# pmac_tx_secure register map
Vendor: Texas Instruments
Registers are 32-bit, access per field, reset 0x0 unless marked. A register's access mark holds for its fields unless they carry their own. Offsets are as the file gives them; [hi:lo] are bit positions; {n}, {i} and the like mark numbered series; <NAME> marks a mode.

## pmac_tx_secure (part 3 of 3)
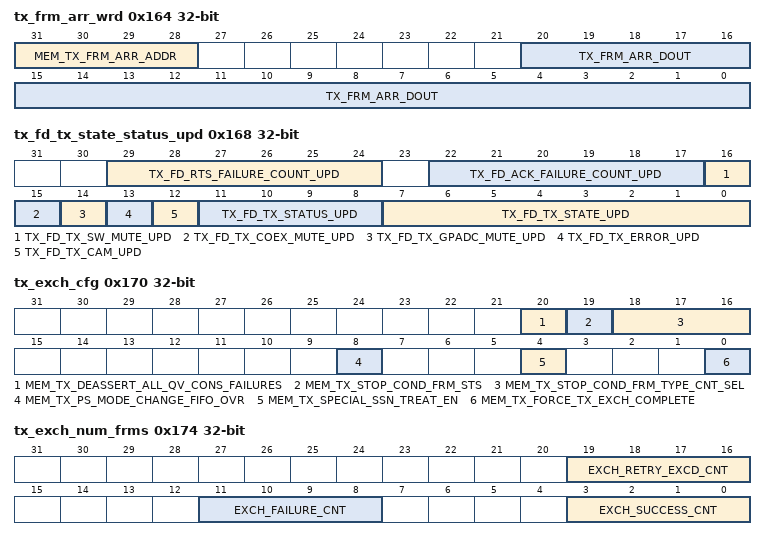
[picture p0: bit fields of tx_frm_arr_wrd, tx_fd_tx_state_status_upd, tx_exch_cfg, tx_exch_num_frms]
0x164 tx_frm_arr_wrd
  [31:28] MEM_TX_FRM_ARR_ADDR rw
  [20:0] TX_FRM_ARR_DOUT ro — read an entry from the trigger/exchange tx_frm_fifo. this is for debug only and can be used only when exchange is idle. the address is taken from the TX_FRM_ARR_ADDR when the array is not accessed by exchange.
0x168 tx_fd_tx_state_status_upd ro — an updated version of the TX_FD_STATE_STATUS. after loading the TX_FD_STATE_STATUS register, this register contains the incremented/cleared coutner values.
  [29:24] TX_FD_RTS_FAILURE_COUNT_UPD — updated failure count to be written to memory/descriptor,
  [22:17] TX_FD_ACK_FAILURE_COUNT_UPD — updated failure count to be written to memory/descriptor,
  [16] TX_FD_TX_SW_MUTE_UPD
  [15] TX_FD_TX_COEX_MUTE_UPD
  [14] TX_FD_TX_GPADC_MUTE_UPD
  [13] TX_FD_TX_ERROR_UPD
  [12] TX_FD_TX_CAM_UPD
  [11:8] TX_FD_TX_STATUS_UPD — updated State to be written to memory/descriptor,
  [7:0] TX_FD_TX_STATE_UPD — updated State to be written to memory/descriptor,
0x16C tx_dummy_reg — auxiliary scripter status. serves just as a read/write address for scripter usages.
  [0] MEM_DUMMY rw — regular read/write register. note that tx scripters write and read from this address.
0x170 tx_exch_cfg reset not defined
  [20] MEM_TX_DEASSERT_ALL_QV_CONS_FAILURES rw — when set, check and deassert all QVs if link's consecutive failure threshold was crossed. if cleared, ignore this event.
  [19] MEM_TX_STOP_COND_FRM_STS rw — 1 : all frames are counted (success, fail etc) 0:successful frame sonly are counted - - PPDU: BA received for aggregation is success - MSDU: for aggregation ,bitmap should be considered - MPDU: for aggregation ,bitmap should be considered
  [18:16] MEM_TX_STOP_COND_FRM_TYPE_CNT_SEL rw — select which kind of transmission will be counted for frame numbe rstop condition: 000: PPDU 001: MSDU (each non-fragmented MPDU + last MPDU fragment) 010 and up: MPDU (incl each fragment)
  [8] MEM_TX_PS_MODE_CHANGE_FIFO_OVR rw — when set, tx frames which cause PS mode change will be pushed to tx_exchange fifo.
  [4] MEM_TX_SPECIAL_SSN_TREAT_EN rw — when set, in case a BA arrives with its SSN field > transmitted frame's sequence number, it is parsed as if it will never be acked. in this case, frame will be marked as if retry limit was exeeded when cleared, frame will be marked as failed and may require a retry.
  [0] MEM_TX_FORCE_TX_EXCH_COMPLETE rw — force select the tx exchange complete FIFO as the destination for all non-retry frames.
0x174 tx_exch_num_frms ro
  [19:16] EXCH_RETRY_EXCD_CNT — number of frames in aggregation which are below SSN and enabled to be clasified as retry exceeded for that reason
  [11:8] EXCH_FAILURE_CNT — number of frames in aggregation which were not AKCed or otherwise decided as failed
  [3:0] EXCH_SUCCESS_CNT — number of frames in aggregation which were AKCed as part of an aggregation
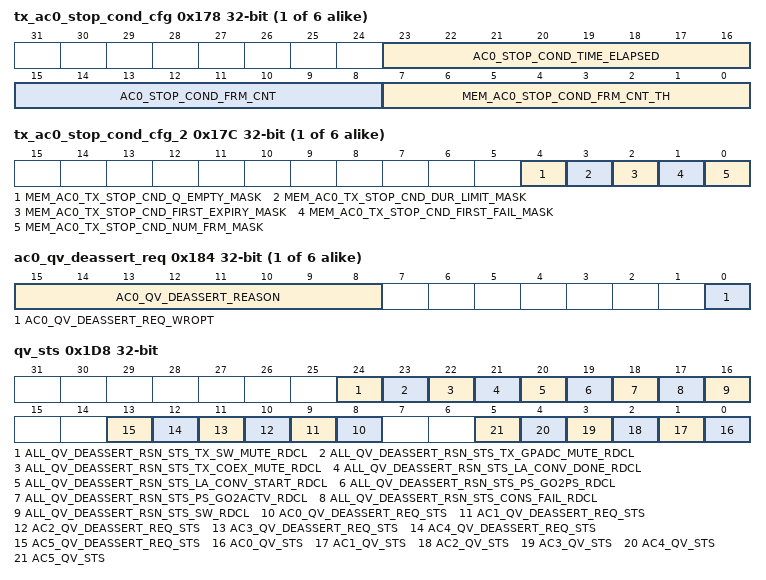
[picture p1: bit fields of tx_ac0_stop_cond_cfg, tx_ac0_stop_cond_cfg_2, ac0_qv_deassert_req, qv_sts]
{0x178+0x10*i} tx_ac{i}_stop_cond_cfg (i=0..5)
  [23:16] AC{i}_STOP_COND_TIME_ELAPSED ro — time from QV assertion.
  [15:8] AC{i}_STOP_COND_FRM_CNT ro — number of frames until stop condition may be applied. frame type is determined by TX_EXCH_CFG register.
  [7:0] MEM_AC{i}_STOP_COND_FRM_CNT_TH rw — number of frames until stop condition may be applied. frame type is determined by TX_EXCH_CFG register.
{0x17C+0x10*i} tx_ac{i}_stop_cond_cfg_2 (i=0..5)
  [4] MEM_AC{i}_TX_STOP_CND_Q_EMPTY_MASK rw, [3] MEM_AC{i}_TX_STOP_CND_DUR_LIMIT_MASK rw, [2] MEM_AC{i}_TX_STOP_CND_FIRST_EXPIRY_MASK rw, [1] MEM_AC{i}_TX_STOP_CND_FIRST_FAIL_MASK rw, [0] MEM_AC{i}_TX_STOP_CND_NUM_FRM_MASK rw
{0x180+0x10*i} ac{i}_qv (i=0..5)
  [0] AC{i}_QV_WROPT rw — queue valid bit. set by FW and cleared by HW. SW may pend a deassertion request via the deassert regs. writing 0 to this address will be ignored.
{0x184+0x10*i} ac{i}_qv_deassert_req (i=0..5)
  [15:8] AC{i}_QV_DEASSERT_REASON ro — bit 0: SW request. bit 1: Candidate Failure. bit 2: TSF Limit Excceded bit 3: Quit when Queue Empty bit 4: Frame Count bit 5: First Fail bit 6: First Expiry bit 7: Duration Limit Excced.
  [0] AC{i}_QV_DEASSERT_REQ_WROPT rw
0x1D8 qv_sts ro — read only status of the Queues condition - QV, QV_DEASSERT etc.
  [24] ALL_QV_DEASSERT_RSN_STS_TX_SW_MUTE_RDCL — ALL qv deasserted due to link adaptation operation mode change (convergence done).
  [23] ALL_QV_DEASSERT_RSN_STS_TX_GPADC_MUTE_RDCL — ALL qv deasserted due to link adaptation operation mode change (convergence done).
  [22] ALL_QV_DEASSERT_RSN_STS_TX_COEX_MUTE_RDCL — ALL qv deasserted due to link adaptation operation mode change (convergence done).
  [21] ALL_QV_DEASSERT_RSN_STS_LA_CONV_DONE_RDCL — ALL qv deasserted due to link adaptation operation mode change (convergence done).
  [20] ALL_QV_DEASSERT_RSN_STS_LA_CONV_START_RDCL — ALL qv deasserted due to link adaptation operation mode change (convergence start).
  [19] ALL_QV_DEASSERT_RSN_STS_PS_GO2PS_RDCL — ALL qv deasserted due to power save mode change
  [18] ALL_QV_DEASSERT_RSN_STS_PS_GO2ACTV_RDCL — ALL qv deasserted due to power save mode change
  [17] ALL_QV_DEASSERT_RSN_STS_CONS_FAIL_RDCL — ALL qv deasserted due to consequtive failure threshold crossing
  [16] ALL_QV_DEASSERT_RSN_STS_SW_RDCL — ALL qv deasserted due to SW request
  [n+8] AC{n}_QV_DEASSERT_REQ_STS (n=0..5) — status of qc deassert request (pending/clear). include this AC's deassert request ORed with the deassert all request.
  [n] AC{n}_QV_STS (n=0..5) — RO of AC{n}_QV bit
0x1DC qv_bitmap
  [5:0] QV_BITMAP_WROPT rw — qv set bitmap - setting a bit will set the relevant AC's QV bit. reading this register will return all ACs QV bit status. reading this address will return the qv status of the 6 ACs. writing 0 to this address will be ignored.
0x1E0 qv_deassert_bitmap
  [5:0] QV_DEASSERT_BITMAP_WROPT rw — setting each bit will create a deassert request to the relevant AC. writing 0 to this address will be ignore. reading this address will return the status of this request: 1 - deassertion pending 0 - idle/done
0x1E4 qv_deassert_all
  [0] QV_DEASSERT_ALL_WRCL wo — setting this bit will create a deassertion request on all ACs. when all ACs are cleared, and interrupt will be asserted. writing 0 to this address will be ignored.
0x1E8 qv_deassert_reason_all ro
  [8:0] ALL_QV_DEASSERT_REASON_RDCL — status of the 'de-assert all' sources, write 0 to clear. sources bitmap: [8] TX mute due to Coex de-grant. [7] TX mute due to GPADC (Thermal). [6] TX mute due to SW request. [5] a link moved to LA functional mode [4] a link moved to LA convergence mode [3] a link moved to PS mode [2] a link moved to active mode [1] a link crossed the consecutive failure threshold [0] SW request for all qv deassertion
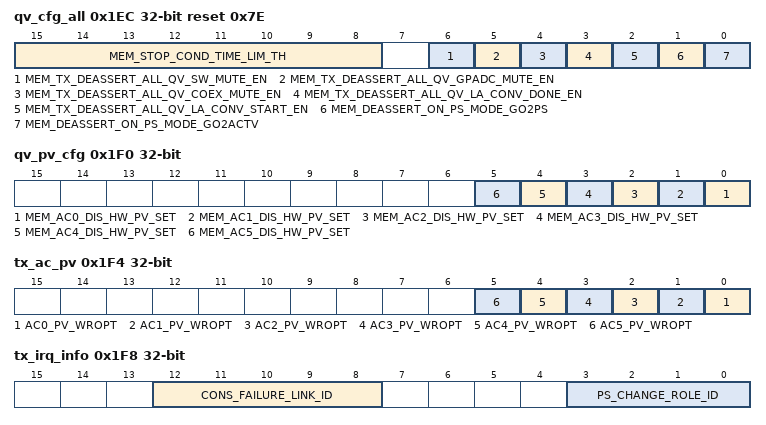
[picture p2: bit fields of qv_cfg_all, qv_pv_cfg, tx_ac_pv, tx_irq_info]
0x1EC qv_cfg_all reset 0x7E
  [15:8] MEM_STOP_COND_TIME_LIM_TH rw — time to be used as a stop condition starting at QV assertion. 9 lsb of the TSF are ignored giving 512usec resolutions. apply to all ACs
  [6] MEM_TX_DEASSERT_ALL_QV_SW_MUTE_EN rw
  [5] MEM_TX_DEASSERT_ALL_QV_GPADC_MUTE_EN rw
  [4] MEM_TX_DEASSERT_ALL_QV_COEX_MUTE_EN rw
  [3] MEM_TX_DEASSERT_ALL_QV_LA_CONV_DONE_EN rw
  [2] MEM_TX_DEASSERT_ALL_QV_LA_CONV_START_EN rw
  [1] MEM_DEASSERT_ON_PS_MODE_GO2PS rw — when set, any link which changes state from active to power save will create a QV de-assert request to all ACs. power save mode change is detected by rx.
  [0] MEM_DEASSERT_ON_PS_MODE_GO2ACTV rw — when set, any link which changes state to from power save to active will create a QV de-assert request to all ACs. power save mode change is detected by rx.
0x1F0 qv_pv_cfg
  [n] MEM_AC{n}_DIS_HW_PV_SET rw (n=0..5) — when set, candidate done will not set the pv. upon candidate completion, an interrupt to SW will be triggered and SW may assert pv.
0x1F4 tx_ac_pv — packet valid indication - if enabled, tx_candidate will assert this bit. if disabled (register QV_PV_CFG) - candidate will not set pv after completion and SW should set the PV bit/s
  [n] AC{n}_PV_WROPT rw (n=0..5)
0x1F8 tx_irq_info ro
  [12:8] CONS_FAILURE_LINK_ID — active link id on last consecutive failure threshold crossing. latched on every thresh cross event.
  [3:0] PS_CHANGE_ROLE_ID — active role id on last ps mode change. latched on every ps mode change event.
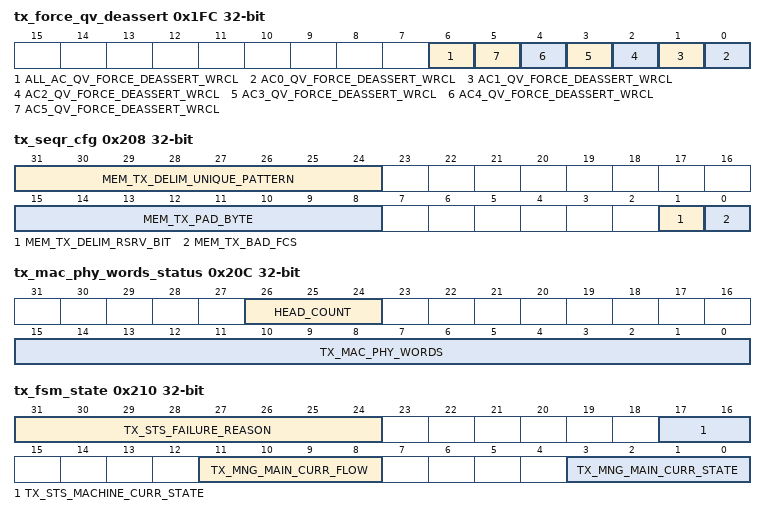
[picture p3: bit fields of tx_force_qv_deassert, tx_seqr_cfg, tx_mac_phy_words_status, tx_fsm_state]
0x1FC tx_force_qv_deassert
  [6] ALL_AC_QV_FORCE_DEASSERT_WRCL wo — writing 1 to this bit will clear all qv and qv deassert request. this applies to single qv and for common qv deassert requests.
  [n] AC{n}_QV_FORCE_DEASSERT_WRCL wo (n=0..5) — writing 1 to this bit will clear both qv and qv deassert request.
0x200 tx_spare_0
  [15:0] TX_SPARE_0_WROPT rw
0x204 tx_spare_1 rw
  [31:0] TX_SPARE_1_WROPT
0x208 tx_seqr_cfg reset not defined
  [31:24] MEM_TX_DELIM_UNIQUE_PATTERN rw — value to be used on head delimiter N pattern
  [15:8] MEM_TX_PAD_BYTE rw — used for padding between mpdus.
  [1] MEM_TX_DELIM_RSRV_BIT rw
  [0] MEM_TX_BAD_FCS rw — when set, flip a bit in the 32bit FCS (corrupt the tx fcs)
0x20C tx_mac_phy_words_status ro — This register holds the MAC-PHY words.
  [26:24] HEAD_COUNT — number of TX_VECTORS words transfered from MAC to PHY. Should be 4.
  [15:0] TX_MAC_PHY_WORDS — number of words transfered from MAC to PHY. this counts is clear on tx_frm_stb (end of frame) and countes on read from PHY. Note, count only data (not header words).
0x210 tx_fsm_state ro — TX FSM State (TX_FSM_STATE)
  [31:24] TX_STS_FAILURE_REASON — bit 0: FCS failure bit 1: Block ACK with Broadcast Address but not Multi-STA Block ACK. bit 2: Multi-STA Block ACK without AID match. bit 3: un-expected RX received (may be the result of FCS) bit 4: RX ended before other indications arrived (e.g AMPDU where no head delimiter was detected) bit 5: Frame aborted before it was over (PHY abort, reject, memory issue etc) bit 6: PLCP header did not arrive
  [17:16] TX_STS_MACHINE_CURR_STATE — tx manager status machine - 0 - idle (true for cases where no response is required as well) 1 - wait for rx status
  [11:8] TX_MNG_MAIN_CURR_FLOW — 0: TX_MAIN_FLOW_IDLE 1: TX_MAIN_FLOW_PROT 2: TX_MAIN_FLOW_DATA 3: TX_MAIN_FLOW_TB_DATA 4: TX_MAIN_FLOW_CF_END 5: TX_MAIN_FLOW_RESP
  [3:0] TX_MNG_MAIN_CURR_STATE — 0: TX_MAIN_IDLE 1: TX_MAIN_WAIT_TRIG_DN 2: TX_MAIN_AGGR_WAIT_NXT 3: TX_MAIN_WAIT_BURST_CAND 4: TX_MAIN_WAIT_STS 5: TX_MAIN_WAIT_EXCH
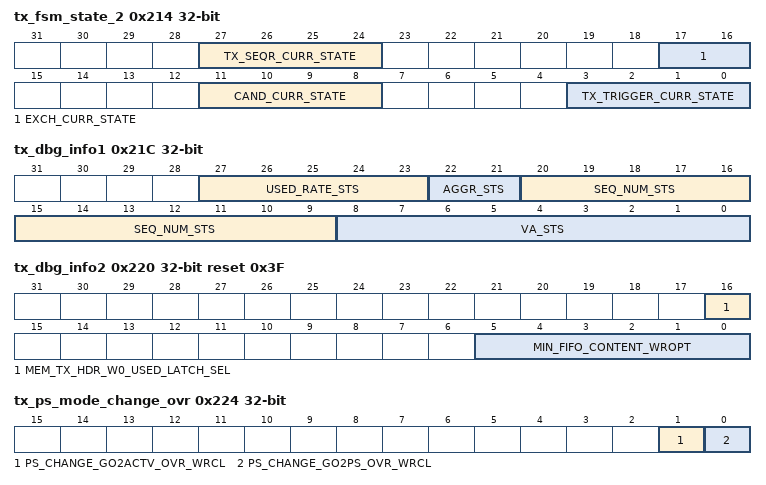
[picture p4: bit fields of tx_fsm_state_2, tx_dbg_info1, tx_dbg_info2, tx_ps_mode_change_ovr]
0x214 tx_fsm_state_2 ro
  [27:24] TX_SEQR_CURR_STATE — 4'd0 : IDLE 4'd1 : WAIT_MPDU_RDY 4'd2 : HEAD_DELIM_WR 4'd3 : FRM_BODY_WR 4'd4 : FCS_WR 4'd5 : PAD_WR 4'd6 : TAIL_DELIM_WR 4'd7 : SYM_PAD_WR 4'd8 : WAIT_FIFO_EMPTY 4'd9 : WAIT_TX_DONE 4'd10 : WAIT_TX_HOLD
  [17:16] EXCH_CURR_STATE — 0: IDLE 1: EXCH_LOAD_REGS 2: EXCH_STORE_REGS 3: EXCH_EVENT_LOG
  [11:8] CAND_CURR_STATE — 4'h0 : IDLE 4'h1 : GATHER_INFO 4'h2 : GET_RATE 4'h3 : CALC_AGGR_DUR 4'h4 : CALC_DATA_DUR 4'h5 : CALC_DATA_IR_DUR 4'h6 : CALC_PROT_DUR 4'h7 : CALC_PROT_IR_DUR 4'h8 : CHK_TXOP_LIMIT 4'h9 : CALC_FRAG_BYTES 4'hA : CALC_FRAG_DUR 4'hB : CHK_FRAG_PROT 4'hC : CANDIDATE_DONE
  [3:0] TX_TRIGGER_CURR_STATE — 4'd0 : TRIG_STATE_IDLE 4'd1 : TRIG_STATE_GATHER_INFO 4'd2 : TRIG_STATE_BUILD_AGGR 4'd3 : TRIG_STATE_CHK_BURST 4'd4 : TRIG_STATE_CALC_IR_DUR 4'd5 : TRIG_STATE_CALC_PARTIAL_DUR 4'd6 : TRIG_STATE_SET_PHY_PARAMS 4'd7 : TRIG_STATE_SET_CMD 4'd8 : TRIG_STATE_UPD_WLAN_HDR 4'd9 : TRIG_STATE_FETCH_WLAN_HDR 4'd10 : TRIG_STATE_PREP_FRM
0x218 tx_winner_tsf_latch_for_exch ro
  [31:0] TX_WINNER_TSF_LATCH_FOR_EXCH — latch the tx winner tsf upon entering the tx trigger. this field can be used by the tx_exchange for writing to the descriptor. for that purpose, if a new tx_winner_stb occured between the tx_trigger and tx_exch, this field will retain its value.
0x21C tx_dbg_info1 ro
  [27:23] USED_RATE_STS
  [22:21] AGGR_STS — 00 - not part of aggr 01 - first in aggr 10 - middle frame 11 - last frame.
  [20:9] SEQ_NUM_STS — sequence number of transmitted frame. in agrregation it will contain the current treated frame (in case this register is read inside the exchange aggr loop)
  [8:0] VA_STS — descriptor ID / Virtual Address of transmitted frame
0x220 tx_dbg_info2 reset 0x3F
  [16] MEM_TX_HDR_W0_USED_LATCH_SEL rw — Select the Header W0 latching trigger: Set 0: trigger by: tx_winner_stb_synched (New for LSB-PG2) Set 1: trigger by: (head_count == 3'h0) & tx_header_rd (legacy)
  [5:0] MIN_FIFO_CONTENT_WROPT rw — holds the minimum number of bytes that the tx fifo reached. its reset value is 0x31. it latches the minimum value under the following conditions: current ppdu length is higher then current min. start latch after at least 5 words were written to the fifo latch as long as tx is writing to the fifo.
0x224 tx_ps_mode_change_ovr — writing '1' to one of the bits will create a pulse in one of the PSD inputs to the tx. this pulse is 'OR'ed with the rx inputs.
  [1] PS_CHANGE_GO2ACTV_OVR_WRCL wo, [0] PS_CHANGE_GO2PS_OVR_WRCL wo
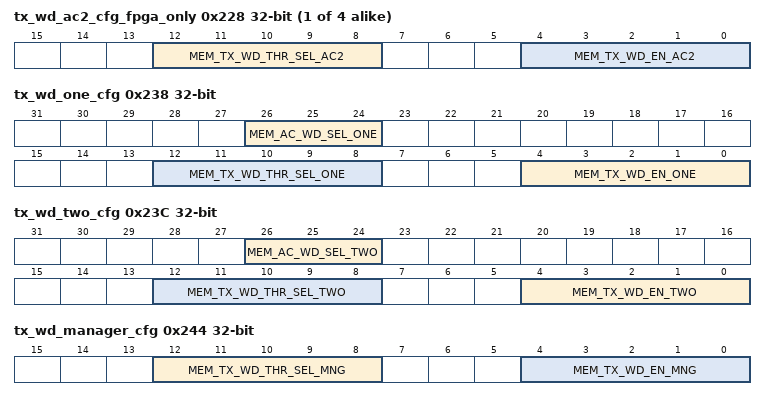
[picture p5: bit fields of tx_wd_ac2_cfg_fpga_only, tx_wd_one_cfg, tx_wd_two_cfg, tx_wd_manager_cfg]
{0x220+4i} tx_wd_ac{i}_cfg_fpga_only reset not defined (i=2..5)
  [12:8] MEM_TX_WD_THR_SEL_AC{i} rw — AC{i} FSM Watchdog threshold select. air dependant states (IDLE, WAIT_TX_START and WAIT_TX_DONE) use msec (low freq) resolution. other use usec (high freq) resolution this bit select which threshold of the corresponding resolution is used.
  [4:0] MEM_TX_WD_EN_AC{i} rw — AC{i} FSM Watchdog en, one bit per FSM state
0x238 tx_wd_one_cfg reset not defined
  [26:24] MEM_AC_WD_SEL_ONE rw — second AC machine Watchdog selected AC
  [12:8] MEM_TX_WD_THR_SEL_ONE rw — second AC FSM Watchdog threshold select. air dependant states (IDLE, WAIT_TX_START and WAIT_TX_DONE) use msec (low freq) resolution. other use usec (high freq) resolution this bit select which threshold of the corresponding resolution is used.
  [4:0] MEM_TX_WD_EN_ONE rw — second AC FSM Watchdog en, one bit per FSM state
0x23C tx_wd_two_cfg reset not defined
  [26:24] MEM_AC_WD_SEL_TWO rw — second AC machine Watchdog selected AC
  [12:8] MEM_TX_WD_THR_SEL_TWO rw — second AC FSM Watchdog threshold select. air dependant states (IDLE, WAIT_TX_START and WAIT_TX_DONE) use msec (low freq) resolution. other use usec (high freq) resolution this bit select which threshold of the corresponding resolution is used.
  [4:0] MEM_TX_WD_EN_TWO rw — second AC FSM Watchdog en, one bit per FSM state
0x240 tx_wd_sts
  [7:0] TX_WD_EXPIRED_IDX_WROPT rw — locked value of the first WD event which occured. any write to this register will clear it to 0. decoding: 8'b001xxxxx: first AC configured wd (xxxxx - ac state) 8'b010xxxxx: second AC configured wd (xxxxx - ac state) 8'b011xxxxx:AC2 wd. FPGA only (xxxxx - ac state) 8'b100xxxxx:AC3 wd. FPGA only (xxxxx - ac state) 8'b101xxxxx:AC4 wd. FPGA only (xxxxx - ac state) 8'b110xxxxx:AC5 wd. FPGA only (xxxxx - ac state) 8'b111xxxxx:manager wd. (xxxxx - ac state)
0x244 tx_wd_manager_cfg reset not defined
  [12:8] MEM_TX_WD_THR_SEL_MNG rw — manager FSM Watchdog threshold select. air dependant states (AGGR_WAIT_NXT and WAIT_STS) use msec (low freq) resolution. other use usec (high freq) resolution this bit select which threshold of the corresponding resolution is used.
  [4:0] MEM_TX_WD_EN_MNG rw — manager FSM Watchdog en, one bit per FSM state
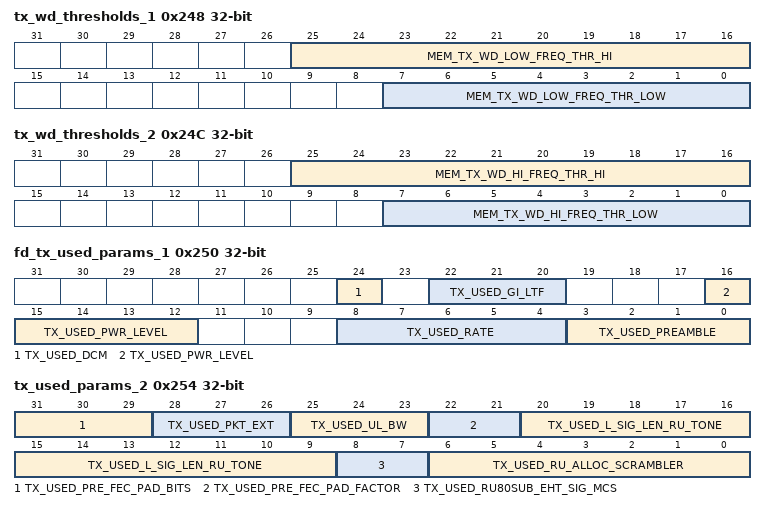
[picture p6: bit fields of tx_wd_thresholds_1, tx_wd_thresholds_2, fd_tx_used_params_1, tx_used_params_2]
0x248 tx_wd_thresholds_1 reset not defined — watchdogs that are used when low frequency (msec) strobes are used.
  [25:16] MEM_TX_WD_LOW_FREQ_THR_HI rw, [7:0] MEM_TX_WD_LOW_FREQ_THR_LOW rw
0x24C tx_wd_thresholds_2 reset not defined — watchdogs that are used when low frequency (msec) strobes are used.
  [25:16] MEM_TX_WD_HI_FREQ_THR_HI rw, [7:0] MEM_TX_WD_HI_FREQ_THR_LOW rw
0x250 fd_tx_used_params_1 ro — Last transmitted PPDU Tx header params
  [24] TX_USED_DCM, [22:20] TX_USED_GI_LTF, [16:12] TX_USED_PWR_LEVEL, [8:4] TX_USED_RATE, [3:0] TX_USED_PREAMBLE
0x254 tx_used_params_2 ro — Last transmitted PPDU Tx header params
  [31:29] TX_USED_PRE_FEC_PAD_BITS
  [28:26] TX_USED_PKT_EXT
  [25:23] TX_USED_UL_BW
  [22:21] TX_USED_PRE_FEC_PAD_FACTOR
  [20:9] TX_USED_L_SIG_LEN_RU_TONE — Two usages: 1. In 11ax NFRP TB PPDU the register stores RU TONE SET INDEX (6:0) and FEEDBACK STATUS (7). 3. O.W the register stores the L_SIG Length.
  [8:7] TX_USED_RU80SUB_EHT_SIG_MCS — Dual use: 1. In 11be TB PPDU the register stores the RU80SUB allocation 2. In 11be MU PPDU the register stores the EHT_SIG_MCS value
  [6:0] TX_USED_RU_ALLOC_SCRAMBLER — Dual use: 1. In 11ax TB PPDU the register stores the RU allocation 2. In 11a/g PPDU the register stores the MU-RTS scrambler init value
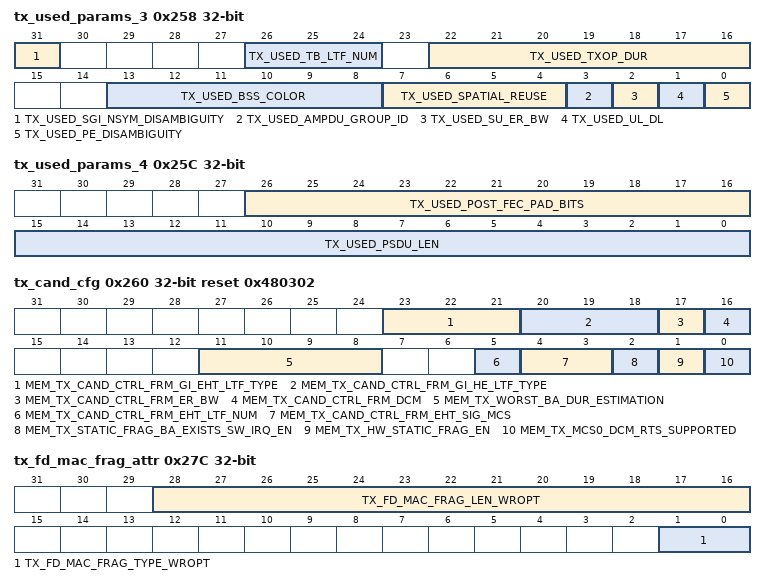
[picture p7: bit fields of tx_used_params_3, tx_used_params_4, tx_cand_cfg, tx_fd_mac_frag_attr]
0x258 tx_used_params_3 ro — Last transmitted PPDU Tx header params
  [31] TX_USED_SGI_NSYM_DISAMBIGUITY, [26:24] TX_USED_TB_LTF_NUM, [22:16] TX_USED_TXOP_DUR, [13:8] TX_USED_BSS_COLOR, [7:4] TX_USED_SPATIAL_REUSE, [3] TX_USED_AMPDU_GROUP_ID, [2] TX_USED_SU_ER_BW, [1] TX_USED_UL_DL, [0] TX_USED_PE_DISAMBIGUITY
0x25C tx_used_params_4 ro — Last transmitted PPDU Tx header params
  [26:16] TX_USED_POST_FEC_PAD_BITS, [15:0] TX_USED_PSDU_LEN
0x260 tx_cand_cfg reset 0x480302
  [23:21] MEM_TX_CAND_CTRL_FRM_GI_EHT_LTF_TYPE rw
  [20:18] MEM_TX_CAND_CTRL_FRM_GI_HE_LTF_TYPE rw
  [17] MEM_TX_CAND_CTRL_FRM_ER_BW rw
  [16] MEM_TX_CAND_CTRL_FRM_DCM rw
  [11:8] MEM_TX_WORST_BA_DUR_ESTIMATION rw — SW shall configure worst block ack duration estimation to be used in RTS duration threshold checking in case aggr is likely to be transmitted (queue holds enough data). if RTS duration threshold < aggregation_estimated_duration + SIFS + worst_block_ack_estimation - RTS/CTS exchange will be done before data transmission. The value's resolution is 32 micro-seconds (4 bits - up to 16x32 micro-seconds)
  [5] MEM_TX_CAND_CTRL_FRM_EHT_LTF_NUM rw
  [4:3] MEM_TX_CAND_CTRL_FRM_EHT_SIG_MCS rw
  [2] MEM_TX_STATIC_FRAG_BA_EXISTS_SW_IRQ_EN rw — Ignore TXOP limit in case only static fragmentation supported and needed, with BA session existsing. Set 1 - SW will get an IRQ and candidate will fail. Set 0 - candidate will transmit frame anyway (ignore TXOP limit).
  [1] MEM_TX_HW_STATIC_FRAG_EN rw — Candidate HW static fragmentation. Set 1 - enable Set 0 - disable
  [0] MEM_TX_MCS0_DCM_RTS_SUPPORTED rw — 1 - In case choosen Rate parameters are 11ax packet MCS0 with DCM, candidate will set (if needed) RTS/CTS exchange in 11ax rate (MCS0 with DCM). 0 - In case choosen Rate parameters are 11ax packet MCS0 with DCM, candidate will set (if needed) RTS/CTS exchange in legacy rate (OFDM 6MBPS).
{0x264+4i} tx_ac{i}_queue_acc_length rw (i=0..3)
  [31:0] TX_AC{i}_QUEUE_ACC_LENGTH_WROPT
0x274 tx_fd_hdr_addr
  [23:0] MEM_TX_FD_HDR_ADDR rw — Frame Header Address.
0x278 tx_fd_pload_addr
  [23:0] TX_FD_PLOAD_ADDR_WROPT rw — Frame Payload Address.
0x27C tx_fd_mac_frag_attr
  [28:16] TX_FD_MAC_FRAG_LEN_WROPT rw — Once fragment size was decided it is saved in this filed. Update by the trigger module at the end of fragment calculation. Used by the trigger module for the aggregation calculation and for the actual TX kick. The exchange module uses this field to update the remaining length field. This field holds only the payload of the fragments, in bytes. SW is capable to set this field prior to PMAC operation to inforce static fragmentation size (required for WEP / TKIP fragmentation).
  [1:0] TX_FD_MAC_FRAG_TYPE_WROPT rw — Valid values - 00 not set yet (or no fragmentation at all) 01 static fragmentation, calculated by SW 10 static fragmentation, calculated by HW 11 Dynamic fragmentation. Static \ dynamic fragmentation defined above. Initial value for PMAC may be 00 or 01 (stating if SW already calculated the fragmentation size). Trigger module may then update it to 10 or 11 based on its decisions.
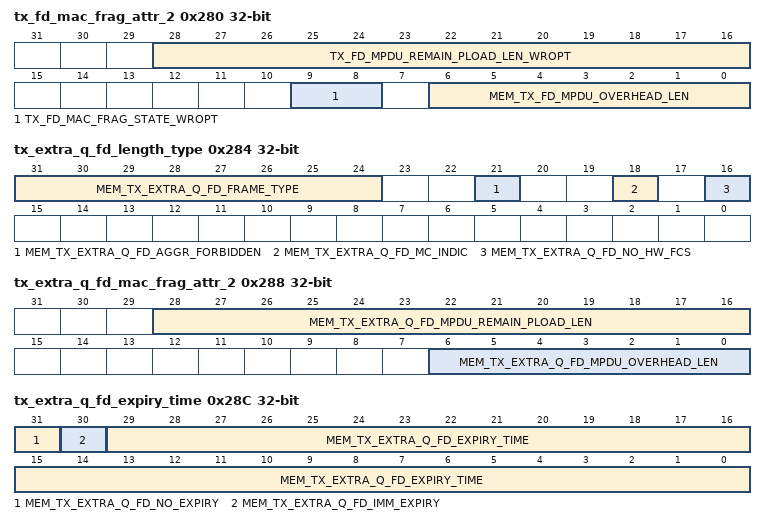
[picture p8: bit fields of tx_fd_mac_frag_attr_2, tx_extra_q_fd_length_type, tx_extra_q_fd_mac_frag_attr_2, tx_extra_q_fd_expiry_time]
0x280 tx_fd_mac_frag_attr_2
  [28:16] TX_FD_MPDU_REMAIN_PLOAD_LEN_WROPT rw — As long as the fragmentation process continues remaining payload length decreases. This value is updated by the TX exchange for every successful fragment, and used by the trigger module for further fragmentation calculation. Initial value is set by the SW, when the descriptor is handed to HW, to the total payload length.
  [9:8] TX_FD_MAC_FRAG_STATE_WROPT rw — The state field is used for managing the fragmentation flow between the trigger module (calculating and sending fragments) and the exchange module (processing the TX status). 00 calculate and send first frag 01 calculate next frag 10 retry current frag 11 re-calc current frag
  [6:0] MEM_TX_FD_MPDU_OVERHEAD_LEN rw — Used for fragmentation calculation. Should include header and tail bytes, including security overhead. Note FCS and HT header bytes that might be dynamically added or removed by the HW are not included.
0x284 tx_extra_q_fd_length_type
  [31:24] MEM_TX_EXTRA_Q_FD_FRAME_TYPE rw — WLAN frame type from WLAN header.
  [21] MEM_TX_EXTRA_Q_FD_AGGR_FORBIDDEN rw — SW override for PMAC decision. Current frame wont be part of aggregation.
  [18] MEM_TX_EXTRA_Q_FD_MC_INDIC rw — WLAN multicast indication from WLAN header.
  [16] MEM_TX_EXTRA_Q_FD_NO_HW_FCS rw — when set, HW do not append FCS
0x288 tx_extra_q_fd_mac_frag_attr_2
  [28:16] MEM_TX_EXTRA_Q_FD_MPDU_REMAIN_PLOAD_LEN rw — As long as the fragmentation process continues remaining payload length decreases. This value is updated by the TX exchange for every successful fragment, and used by the trigger module for further fragmentation calculation. Initial value is set by the SW, when the descriptor is handed to HW, to the total payload length.
  [6:0] MEM_TX_EXTRA_Q_FD_MPDU_OVERHEAD_LEN rw — Used for fragmentation calculation. Should include header and tail bytes, including security overhead. Note FCS and HT header bytes that might be dynamically added or removed by the HW are not included.
0x28C tx_extra_q_fd_expiry_time rw
  [31] MEM_TX_EXTRA_Q_FD_NO_EXPIRY — when set, current frame is not subject to expiry check
  [30] MEM_TX_EXTRA_Q_FD_IMM_EXPIRY — when set, frame is expired immediately after candidate processing.
  [29:0] MEM_TX_EXTRA_Q_FD_EXPIRY_TIME — expiry time in TSF. time is absolute time and not relative to current TSF.
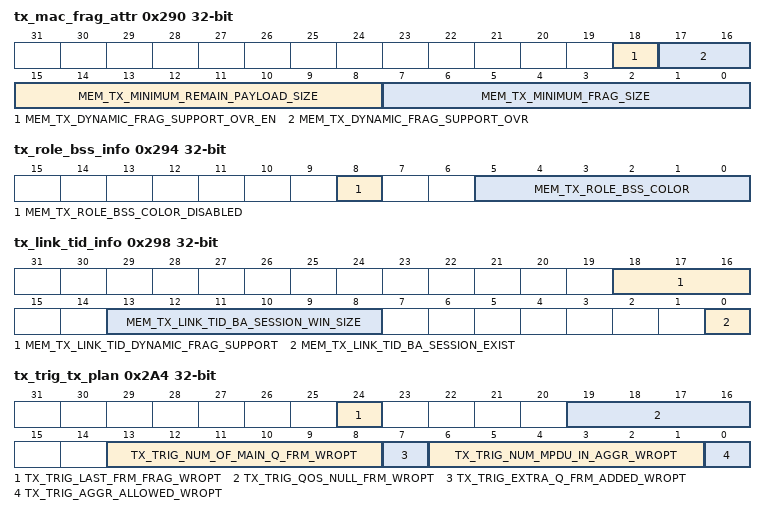
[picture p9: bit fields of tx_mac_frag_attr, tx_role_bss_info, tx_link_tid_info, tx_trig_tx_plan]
0x290 tx_mac_frag_attr
  [18] MEM_TX_DYNAMIC_FRAG_SUPPORT_OVR_EN rw — Set 1 - SW overrides Dynamic Fragmentation level. Set 0 - Dynamic Fragmentation level will be derived from link capability.
  [17:16] MEM_TX_DYNAMIC_FRAG_SUPPORT_OVR rw — Set to 0 for no support for dynamic fragmentation. Set to 1 for level 1 dynamic fragmentation fragment may be sent only as single MPDU or S-MPDU. The response for such frame should be ack. Set to 2 for level 2 dynamic fragmentation fragments may be sent in aggregation, but no more than one fragment for each MSDU. Set to 3 for level 3 dynamic fragmentation even more than one fragment of the same MSDU may be included in the same aggregation. In this case different structure of block ack is required.
  [15:8] MEM_TX_MINIMUM_REMAIN_PAYLOAD_SIZE rw — Determines the minimum remaining payload size, if remaining payload is less than this value, fragmentation will not be applied. Byte resulotion (up to 256 bytes).
  [7:0] MEM_TX_MINIMUM_FRAG_SIZE rw — Indicates the minimum frame body size in octets of the first fragment.
0x294 tx_role_bss_info
  [8] MEM_TX_ROLE_BSS_COLOR_DISABLED rw — Set 1 - Disable BSS Color. Set 0 - O.W.
  [5:0] MEM_TX_ROLE_BSS_COLOR rw — The BSS Color subfield is an unsigned integer whose value is the BSS Color.
0x298 tx_link_tid_info
  [18:16] MEM_TX_LINK_TID_DYNAMIC_FRAG_SUPPORT rw — Set to 0 for no support for dynamic fragmentation. Set to 1 for level 1 dynamic fragmentation fragment may be sent only as single MPDU or S-MPDU. The response for such frame should be ack. Set to 2 for level 2 dynamic fragmentation fragments may be sent in aggregation, but no more than one fragment for each MSDU. Set to 3 for level 3 dynamic fragmentation even more than one fragment of the same MSDU may be included in the same aggregation. In this case different structure of block ack is required.
  [13:8] MEM_TX_LINK_TID_BA_SESSION_WIN_SIZE rw — window size HW uses window size + 1 in order to allow a 64 window size
  [0] MEM_TX_LINK_TID_BA_SESSION_EXIST rw
0x29C tx_spatial_reuse
  [3:0] MEM_TX_SPATIAL_REUSE rw
0x2A0 tx_trig_accum_apep_len
  [15:0] TX_TRIG_ACCUM_APEP_LEN_WROPT rw — Current Transmitted PPDU Accumlated Apep Length, as calculated by TX Trigger module. Accumlated Apep Length captures all MAC data length excluding MAC padding that might be needed.
0x2A4 tx_trig_tx_plan — In EDCA/TB Transmission, TX Trigger calculate the TX Plan (Aggregation calculation decision) before starting to transmit frames to the AIR.
  [24] TX_TRIG_LAST_FRM_FRAG_WROPT rw — In case dynamic fragmentation is supported. Set 1 - Last frame in aggregation was fragmented to fit into remaining TXOP. Set 0 - Last frame in aggregation was not fragmented.
  [19:16] TX_TRIG_QOS_NULL_FRM_WROPT rw — QoS Null vector: Set Bit 0 - QoS-Null frame was added to aggergation reporting AC0 status. Set Bit 1 - QoS-Null frame was added to aggergation reporting AC1 status. Set Bit 2 - QoS-Null frame was added to aggergation reporting AC2 status. Set Bit 3 - QoS-Null frame was added to aggergation reporting AC3 status.
  [13:8] TX_TRIG_NUM_OF_MAIN_Q_FRM_WROPT rw — Num of Frames aggregated from Main queue.
  [7] TX_TRIG_EXTRA_Q_FRM_ADDED_WROPT rw — Set 1 - Mngt/Ctrl frame is aggregated from extra queue. Set 0 - No Mngt/Ctrl frame is aggregated from extra queue.
  [6:1] TX_TRIG_NUM_MPDU_IN_AGGR_WROPT rw — Num of MPDUs in the current transmission. Including - Main queue frames, Extra queue frame, HW GEN QoS-null frames.
  [0] TX_TRIG_AGGR_ALLOWED_WROPT rw — Set 1 - An A-MPDU will be transmitted in current TXOP. Set 0 - Single MPDU will be transmitted in current TXOP.
0x2A8 tx_scrpt_extra_q_va_idx reset not defined
  [8:0] MEM_TX_SCRPT_EXTRA_Q_VA_IDX rw — Virtual index as popped from a descriptor fifo (Extra queue).
0x2AC tx_trig_ampdu_start_window
  [11:0] TX_TRIG_AMPDU_START_WINDOW_WROPT rw — sequence number of the head of the tx queue or if already set to the first frame in the queue - this frame's seq num.
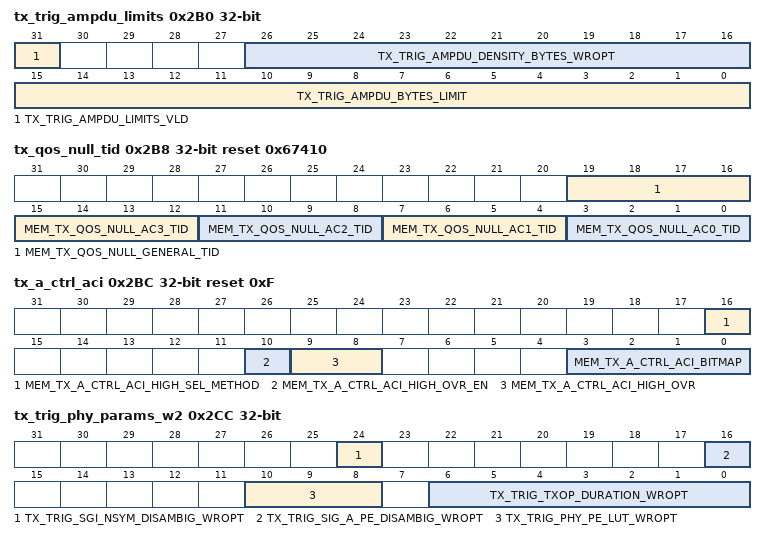
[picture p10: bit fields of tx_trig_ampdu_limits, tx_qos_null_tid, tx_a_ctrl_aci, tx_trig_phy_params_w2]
0x2B0 tx_trig_ampdu_limits reset not defined
  [31] TX_TRIG_AMPDU_LIMITS_VLD ro — when set, the values in this register are valid.
  [26:16] TX_TRIG_AMPDU_DENSITY_BYTES_WROPT rw — HW result of the number of bytes that fit into the minimum spacing supported by the peer.
  [15:0] TX_TRIG_AMPDU_BYTES_LIMIT ro — limit in bytes derived from available payload duration multiplied by tx rate
0x2B4 tx_cfg_extra_q_ac reset 0x5
  [2:0] MEM_TX_CFG_EXTRA_Q_AC rw — Extra Queue Selection: Set to 0 - AC0 Set to 1 - AC1 Set to 2 - AC2 Set to 3 - AC3 Set to 4 - AC4 Set to 5 - AC5 O.W. - Not valid. SW should push only management/control frames to this queues. This frames will be added (one at a time) to copmlex aggeregation built by trigger module.
0x2B8 tx_qos_null_tid reset 0x67410
  [19:16] MEM_TX_QOS_NULL_GENERAL_TID rw — General TID value, this value is inserted in the HW Generated QoS-Null frame as a response to BQRP/BSRP or in case of basic trigger where all queues are empty.
  [4n+3:4n] MEM_TX_QOS_NULL_AC{n}_TID rw (n=0..3) — TID of TX Queue transmitted in AC{n}. This value is inserted in the HW Generated QoS-Null frame that intend to report AC{n} queue status.
0x2BC tx_a_ctrl_aci reset 0xF
  [16] MEM_TX_A_CTRL_ACI_HIGH_SEL_METHOD rw — Selection Method: Set 1 = Strict Priority Set 0 = Queue Size Priority
  [10] MEM_TX_A_CTRL_ACI_HIGH_OVR_EN rw — SW overrides PMAC decision on which AC to report in A-Ctrl.
  [9:8] MEM_TX_A_CTRL_ACI_HIGH_OVR rw — One specific AC is selected (from the ACI bitmap), and its queue size is reported seperatly in queue size high. Set 0 - Report AC0 queue size. Set 1 - Report AC1 queue size. Set 2 - Report AC2 queue size. Set 3 - Report AC3 queue size. O.W. - Not valid.
  [3:0] MEM_TX_A_CTRL_ACI_BITMAP rw — ACI bitmap SW value for which ACs the queue size is currently reported. ACI bitmap defines the currently operational ACs. Set/Clr Bit 0 - Enable/Disable AC0 queue size report. Set/Clr Bit 1 - Enable/Disable AC1 queue size report. Set/Clr Bit 2 - Enable/Disable AC2 queue size report. Set/Clr Bit 3 - Enable/Disable AC3 queue size report.
0x2C0 tx_a_ctrl_bqr
  [9:0] MEM_TX_A_CTRL_BQR rw — Bandwidth query report (BQR) - Stations are supposed to report to the AP the channel availability as seen from their point of view. SW should set this value, and PMAC will report this in A-Ctrl BQR element.
0x2C4 tx_a_ctrl_general_purpose rw
  [31:0] MEM_TX_A_CTRL_GENERAL_PURPOSE — A general purpose A-Ctrl element to be reported to AP. SW shall set this value (32 bits), and configurate the selection override to select this custom element.
0x2C8 tx_trig_phy_params_w1 — Word #1 in the TX_VECTOR passed to PHY through TX MAC-PHY IF.
  [11:0] TX_TRIG_L_SIG_LENGTH_WROPT rw — L_SIG Length is caluclated by TX trigger module, and can be overriden using this register before passing it to TX MAC-PHY IF.
0x2CC tx_trig_phy_params_w2 — Word #2 in the TX_VECTOR passed to PHY through TX MAC-PHY IF.
  [24] TX_TRIG_SGI_NSYM_DISAMBIG_WROPT rw — SGI_NSYM Disambiguity is caluclated by TX trigger module, and can be overriden using this register before passing it to TX MAC-PHY IF.
  [16] TX_TRIG_SIG_A_PE_DISAMBIG_WROPT rw — SIG_A_PE Disambiguity is caluclated by TX trigger module, and can be overriden using this register before passing it to TX MAC-PHY IF.
  [10:8] TX_TRIG_PHY_PE_LUT_WROPT rw — PHY PE LUT is caluclated by TX trigger module, and can be overriden using this register before passing it to TX MAC-PHY IF.
  [6:0] TX_TRIG_TXOP_DURATION_WROPT rw — TXOP Duration is caluclated by TX trigger module, and can be overriden using this register before passing it to TX MAC-PHY IF.
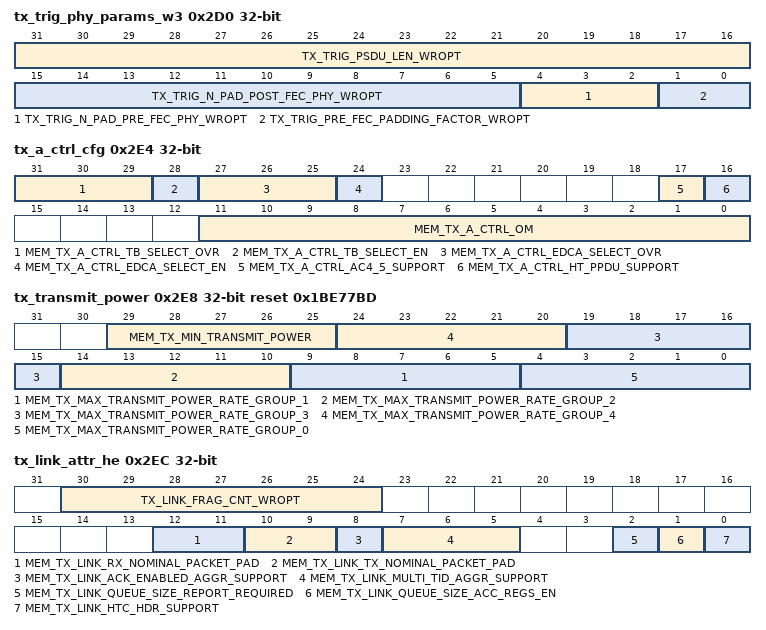
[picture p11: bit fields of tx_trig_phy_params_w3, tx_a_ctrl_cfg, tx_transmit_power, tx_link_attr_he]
0x2D0 tx_trig_phy_params_w3 rw — Word #3 in the TX_VECTOR passed to PHY through TX MAC-PHY IF.
  [31:16] TX_TRIG_PSDU_LEN_WROPT — PSDU LENGTH is caluclated by TX trigger module, and can be overriden using this register before passing it to TX MAC-PHY IF.
  [15:5] TX_TRIG_N_PAD_POST_FEC_PHY_WROPT — N PAD POST FEC PHY is caluclated by TX trigger module, and can be overriden using this register before passing it to TX MAC-PHY IF.
  [4:2] TX_TRIG_N_PAD_PRE_FEC_PHY_WROPT — N_PAD PRE FEC PHY is caluclated by TX trigger module, and can be overriden using this register before passing it to TX MAC-PHY IF.
  [1:0] TX_TRIG_PRE_FEC_PADDING_FACTOR_WROPT — PRE FEC Padding Factor is caluclated by TX trigger module, and can be overriden using this register before passing it to TX MAC-PHY IF.
0x2D8 tx_wlan_hdr_htc_hdr rw — Contains the HTC header word as read from the RAM and modified by PMAC.
  [31:0] TX_WLAN_HDR_HTC_HDR_WROPT
0x2DC tx_extra_q_seq_num — Extra queue sequence number
  [11:0] TX_EXTRA_Q_SEQ_NUM_WROPT rw
0x2E0 tx_scrpt_base7_offset — Base7 offset is added to Base7 in TX Scripter wrapper. Increment and decrement logic was implemented to ease Scripter update, Byte Enable - 2'b01 : (+) Increment previous value (with immediate value) Byte Enable - 2'b10 : (-) Decrement previous value (with immediate value) Byte Enable - 2'b11 : (ld) Initilize previous value (with immediate value)
  [15:0] TX_SCRPT_BASE7_OFFSET_WROPT rw — Immedite value written by scripter can be only one byte width [7:0].
0x2E4 tx_a_ctrl_cfg
  [31:29] MEM_TX_A_CTRL_TB_SELECT_OVR rw — A-Control Type: Set 0 - Operating mode (OM) Set 1 - Buffer status report (BSR) Set 2 - UL power headroom (UPH) Set 3 - Bandwidth query report (BQR) Set 4 - Operating mode (OM) + UL power headroom (UPH) O.W. - SW General Purpose Type.
  [28] MEM_TX_A_CTRL_TB_SELECT_EN rw — SW overrides PMAC decision regarding A-Control type selection (in HTC Header), in TB transmission.
  [27:25] MEM_TX_A_CTRL_EDCA_SELECT_OVR rw — A-Control Type: Set 0 - Operating mode (OM) Set 1 - Buffer status report (BSR) Set 2 - UL power headroom (UPH) Set 3 - Bandwidth query report (BQR) Set 4 - Operating mode (OM) + UL power headroom (UPH) O.W. - SW General Purpose Type.
  [24] MEM_TX_A_CTRL_EDCA_SELECT_EN rw — SW overrides PMAC decision regarding A-Control type selection (in HTC Header) in EDCA transmission.
  [17] MEM_TX_A_CTRL_AC4_5_SUPPORT rw — Set 1 - Enable HW to accumlate AC4 and AC5 into A-CTRL calculations (e.g. BSR). Set 0 - Disable HW to accumlate AC4 and AC5 into A-CTRL calculations (e.g. BSR). In case set 1, AC4 and AC5 will be accumulated with AC3 queue length and will be reported together in A-CTRL (but not in QoS header).
  [16] MEM_TX_A_CTRL_HT_PPDU_SUPPORT rw — Set 1 - Enable HW insertion of HTC Header (A-Ctrl) in HT PPDU (in addition to HE PPDU). Set 0 - Disable HW insertion of HTC Header (A-Ctrl) in HT PPDU (in addition to HE PPDU).
  [11:0] MEM_TX_A_CTRL_OM rw — Operating mode (OM) - Most of the operation mode's parameters are constnt in the cc33xx (supporting only 20Mhz bandwidth, and single sptail stream). The only dynamic parameter 'UL MU disable' that can be modified during operation, if ever required.
0x2E8 tx_transmit_power reset 0x1BE77BD — SW Specifies TX Power transmission boundaries (MAX/MIN). Max TX Power is per rate group. This value is used by PMAC to calculate UPH A-Ctrl Element. -10 to 20 [dBm]
  [29:25] MEM_TX_MIN_TRANSMIT_POWER rw — Rate Group: all MCS rates.
  [5n+4:5n] MEM_TX_MAX_TRANSMIT_POWER_RATE_GROUP_{n} rw (n=1..4) — Rate Group: MCS{n+3}.
  [4:0] MEM_TX_MAX_TRANSMIT_POWER_RATE_GROUP_0 rw — Rate Group: MCS0, MCS1, MCS2, MCS3.
0x2EC tx_link_attr_he
  [30:24] TX_LINK_FRAG_CNT_WROPT rw — Counts the number of fragmented MPDUs that were concurrently sent to Peer.
  [12:11] MEM_TX_LINK_RX_NOMINAL_PACKET_PAD rw — Indicates the nominal packet padding to be used. Set to 0 if the nominal packet padding is 0 micro sec Set to 1 if the nominal packet padding is 8 micro sec Set to 2 if the nominal packet padding is 16 micro sec The value 3 is reserved.
  [10:9] MEM_TX_LINK_TX_NOMINAL_PACKET_PAD rw — Indicates the nominal packet padding to be used. Set to 0 if the nominal packet padding is 0 micro sec Set to 1 if the nominal packet padding is 8 micro sec Set to 2 if the nominal packet padding is 16 micro sec The value 3 is reserved.
  [8] MEM_TX_LINK_ACK_ENABLED_AGGR_SUPPORT rw — Indicates support by a STA to receive an A-MPDU that contains two or more frames at least one of which solicits an Ack frame or acknowledgment context in a Multi-STA BlockAck frame. Set to 1 if the STA supports reception of this A-MPDU format. Set to 0 otherwise.
  [7:5] MEM_TX_LINK_MULTI_TID_AGGR_SUPPORT rw — Indicates the number of TIDs of QoS Data frames that an HE STA can receive in a multi-TID AMPDU. Set to the number of TIDs minius 1 of QoS Data frames that an HE STA can receive in a multi-TID A-MPDU.
  [2] MEM_TX_LINK_QUEUE_SIZE_REPORT_REQUIRED rw — Set 1 - Link requires queue size report in QoS header. Set 0 - Link doesn't require queue size report in QoS header.
  [1] MEM_TX_LINK_QUEUE_SIZE_ACC_REGS_EN rw — Set 1 - Enable HW update of QS accumlators (decrementing sucssefully transmitted frames). Set 0 - Disable HW update of QS accumlators (decrementing sucssefully transmitted frames).
  [0] MEM_TX_LINK_HTC_HDR_SUPPORT rw — Support insertion of HTC Header (A-Ctrl).
0x2F0 tx_role_tsf_sw_prot_end — End of the protection period (TSF) set by SW in Role DB, as part of the long NAV protection frames (CTS) sequence. These CTS frames are generated by SW to protect the air until end of protection period (TSF).
  [17:0] MEM_TX_ROLE_TSF_SW_PROT_END rw
0x2F4 tx_role_default_pe_duration — Duration of the PE (Packet Extension) to be transmitted. Integer value: 0,4,8,12,16 micro-second.
  [2:0] MEM_TX_ROLE_DEFAULT_PE_DURATION rw
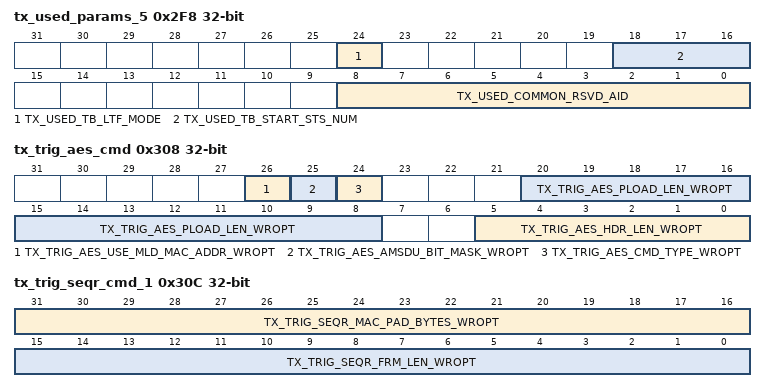
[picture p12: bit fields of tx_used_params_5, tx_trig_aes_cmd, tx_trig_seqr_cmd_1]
0x2F8 tx_used_params_5 ro — Last transmitted PPDU Tx header params
  [24] TX_USED_TB_LTF_MODE
  [18:16] TX_USED_TB_START_STS_NUM
  [8:0] TX_USED_COMMON_RSVD_AID — Triple use: 1. In 11ax NFRP TB PPDU the register stores the SIG-A2 reserved bits. 2. In 11ax TB PPDU the register stores the SIG-A2 reserved bits. 3. In VHT PPDU the register stores the partial aid.
0x2FC tx_trig_aes_hdr_addr — AES Frame Header Address.
  [23:0] TX_TRIG_AES_HDR_ADDR_WROPT rw
0x300 tx_trig_aes_pload_addr — AES Frame Payload Address
  [23:0] TX_TRIG_AES_PLOAD_ADDR_WROPT rw
0x304 tx_trig_aes_key_ptr — AES Key Pointer.
  [23:0] TX_TRIG_AES_KEY_PTR_WROPT rw
0x308 tx_trig_aes_cmd
  [26] TX_TRIG_AES_USE_MLD_MAC_ADDR_WROPT rw — Selector for key addresses
  [25] TX_TRIG_AES_AMSDU_BIT_MASK_WROPT rw — Set 0 - Mask AMSDU bit Set 1 - O.W.
  [24] TX_TRIG_AES_CMD_TYPE_WROPT rw — Set 0 - For AES dec/enc operation. Set 1 - For only DMA operation.
  [20:8] TX_TRIG_AES_PLOAD_LEN_WROPT rw — Frame payload length, can include the whole payload or a fragment size.
  [5:0] TX_TRIG_AES_HDR_LEN_WROPT rw — Frame Header Length include: WLAN HDR + HTC HDR (if added).
0x30C tx_trig_seqr_cmd_1 rw
  [31:16] TX_TRIG_SEQR_MAC_PAD_BYTES_WROPT — Number of bytes that TX sequncer is required to pad at the end of current MPDU. This padding is required in order to complete certain constellation symbols.
  [15:0] TX_TRIG_SEQR_FRM_LEN_WROPT — Frame Length includes: WLAN HDR + HTC HDR + SEC HDR + PAYLOAD LENGTH + MIC The HEAD DELIM, FCS and MAC PAD (TAIL DELIM) are added by TX sequencer.
